VERSION "HIPBNYYYYYYYYYYYYYYYYYYYYYYYYYYYYYYYYYYYYY/4/%%%/4/'%**4YYY///"

NS_ :

BS_:

BU_:

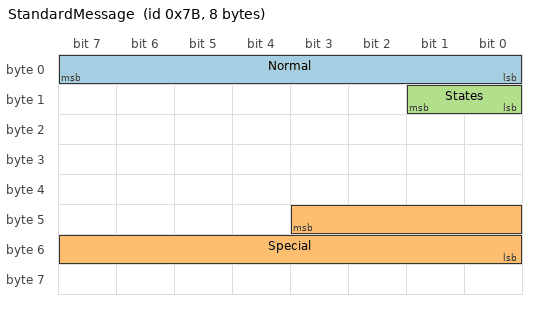
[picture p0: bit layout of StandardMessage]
BO_ 123 StandardMessage: 8 Vector__XXX BANANA
 SG_ Normal : 0|8@1+ (1,0) [0|255] "A" Vector__XXX
 SG_ Special : 43|12@0- (0.5,-50) [-50|300] "V" Vector__XXX
 SG_ States : 8|2@1+ (1,0) [0|10] "" Vector__XXX

BO_ 2566906689 ExtendedMessage: 8 Vector__XXX
 SG_ Multiplexor M : 0|8@1+ (1,0) [0|255] "" Vector__XXX
 SG_ BatteryCell1Voltage m0 : 8|16@1+ (1,0) [0|65535] "V" Vector__XXX
 SG_ BatteryCell2Voltage m1 : 8|16@1+ (1,0) [0|65535] "V" Vector__XXX

VAL_ 123 States 0 "Off" 1 "On" 2 "Blinking" 3 "Unavailable" ;
